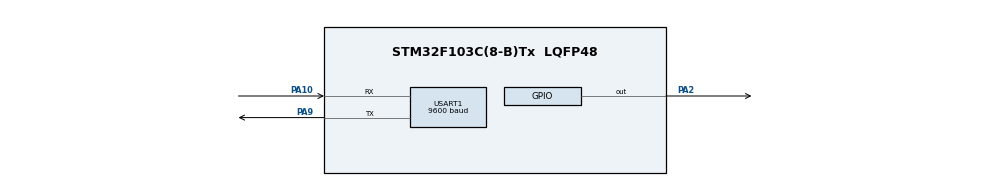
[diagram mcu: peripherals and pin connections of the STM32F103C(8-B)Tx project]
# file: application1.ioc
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Mcu.Family=STM32F1
Mcu.Name=STM32F103C(8-B)Tx
Mcu.Package=LQFP48
NVIC.PriorityGroup=NVIC_PRIORITYGROUP_4
NVIC.USART1_IRQn=true\:0\:0\:false\:false\:true\:true\:true\:true
PA10.Mode=Asynchronous
PA10.Signal=USART1_RX
PA13.Mode=Serial_Wire
PA13.Signal=SYS_JTMS-SWDIO
PA14.Mode=Serial_Wire
PA14.Signal=SYS_JTCK-SWCLK
PA2.Signal=GPIO_Output
PA9.Mode=Asynchronous
PA9.Signal=USART1_TX
ProjectManager.HeapSize=0x200
ProjectManager.StackSize=0x400
ProjectManager.TargetToolchain=STM32CubeIDE
RCC.APB1Freq_Value=8000000
RCC.APB2Freq_Value=8000000
USART1.BaudRate=9600
USART1.VirtualMode=VM_ASYNC
board=custom

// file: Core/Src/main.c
/* USER CODE BEGIN Header */
/**
  ******************************************************************************
  * @file           : main.c
  * @brief          : Main program body
  ******************************************************************************
  * @attention
  *
  * Copyright (c) 2025 STMicroelectronics.
  * All rights reserved.
  *
  * This software is licensed under terms that can be found in the LICENSE file
  * in the root directory of this software component.
  * If no LICENSE file comes with this software, it is provided AS-IS.
  *
  ******************************************************************************
  */
/* USER CODE END Header */
#include "main.h"

/* USER CODE BEGIN Includes */
#include <stdio.h>
#include <string.h>
#include <stdlib.h>
/* USER CODE END Includes */

/* USER CODE BEGIN PD */
#define FIRMWARE_VERSION			"1.0"
#define SLOT_2_ADDR					0x08009800	 //38 page
#define ADDR_OF_SLOT_NO				0x08002800   //10 page
#define Update_Firmware_Cmd			"101"
#define Stop_Update_Firmware_Cmd    "102"
/* USER CODE END PD */

UART_HandleTypeDef huart1;

/* USER CODE BEGIN PV */
char  tx_data[150] = {0};
uint32_t flash_write_data[1024];
uint32_t PageError = 0;
HAL_StatusTypeDef status = HAL_OK;

volatile char Rx_data[1]={0};
char data_buff[100]={};
volatile uint8_t startData = 0, isDataComp =0, indx=0,FirmwareUpdate=0;

int file_size = 0;
uint8_t fw_update_start=0,fw_update_cplt=0;
FLASH_EraseInitTypeDef fwupdate_EraseInitStruct = {0};
/* USER CODE END PV */

void SystemClock_Config(void);
static void MX_GPIO_Init(void);
static void MX_USART1_UART_Init(void);
/* USER CODE BEGIN PFP */
void Write_into_Flash(uint32_t addr,uint32_t data[],uint16_t size, uint32_t NbPages);

/*functions for firmware update*/
uint8_t PageErase_inFlash(int numOfPages);
/* USER CODE END PFP */

int main(void)
{

  /* MCU Configuration--------------------------------------------------------*/

  /* Reset of all peripherals, Initializes the Flash interface and the Systick. */
  HAL_Init();

  /* Configure the system clock */
  SystemClock_Config();

  /* Initialize all configured peripherals */
  MX_GPIO_Init();
  MX_USART1_UART_Init();
  /* USER CODE BEGIN 2 */
  HAL_UART_Receive_IT(&huart1,(uint8_t*)Rx_data,1);

  sprintf(tx_data,"Application 1 loaded successfully \n");
  HAL_UART_Transmit(&huart1, (uint8_t*)tx_data, strlen(tx_data), 1000);

  HAL_GPIO_WritePin(GPIOC,GPIO_PIN_13,1);

  flash_write_data[0] = 1;
  Write_into_Flash((uint32_t)ADDR_OF_SLOT_NO,flash_write_data,1,1);

  /* USER CODE END 2 */

  /* Infinite loop */
  /* USER CODE BEGIN WHILE */
  while (1)
  {
	  HAL_GPIO_TogglePin(GPIOA,GPIO_PIN_2);
	  HAL_Delay(300);
	  if(isDataComp)
	  {
	  	HAL_UART_Transmit(&huart1, (uint8_t*)data_buff,strlen(data_buff),100);
	  	sprintf(tx_data,"is there firmware update: %d\n",FirmwareUpdate);
	    HAL_UART_Transmit(&huart1, (uint8_t*)tx_data, strlen(tx_data), 1000);

	  	if(strcmp(Update_Firmware_Cmd,data_buff) == 0)
	  	{
	  		sprintf(tx_data,"*OK#");
	  		HAL_UART_Transmit(&huart1, (uint8_t*)tx_data, strlen(tx_data), 1000);
	  		FirmwareUpdate = 1;

	  	}
	  	else if(strcmp(Stop_Update_Firmware_Cmd,data_buff) == 0)
	  	{
	  		sprintf(tx_data,"\n Stopping firmware update and rebooting\n");
	  		HAL_UART_Transmit(&huart1, (uint8_t*)tx_data, strlen(tx_data), 1000);
	  	}
	  	else if(FirmwareUpdate)
	  	{
	  		file_size = atoi(data_buff);  //file size should be in bytes
	  		int x = file_size/1000;       //no. of pages
	  		sprintf(tx_data,"\n file size: %d B\n",file_size);
	  		HAL_UART_Transmit(&huart1, (uint8_t*)tx_data, strlen(tx_data), 1000);
	  		if((x > 0) && (x <= 27))
	  		{
	  			 HAL_FLASH_Unlock();
	  			 fw_update_start = PageErase_inFlash(x);
	  			 if(fw_update_start == HAL_OK)
	  			 {
	  				 sprintf(tx_data,"\n start update\n");
	  				 HAL_UART_Transmit(&huart1, (uint8_t*)tx_data, strlen(tx_data), 1000);
	  			 }
	  			 else HAL_FLASH_Lock();

	  		}
	  		FirmwareUpdate=0;
	  	}
	  	isDataComp = 0;
	  }
    /* USER CODE END WHILE */

  }
}

void SystemClock_Config(void)
{
  RCC_OscInitTypeDef RCC_OscInitStruct = {0};
  RCC_ClkInitTypeDef RCC_ClkInitStruct = {0};

  /** Initializes the RCC Oscillators according to the specified parameters
  * in the RCC_OscInitTypeDef structure.
  */
  RCC_OscInitStruct.OscillatorType = RCC_OSCILLATORTYPE_HSI;
  RCC_OscInitStruct.HSIState = RCC_HSI_ON;
  RCC_OscInitStruct.HSICalibrationValue = RCC_HSICALIBRATION_DEFAULT;
  RCC_OscInitStruct.PLL.PLLState = RCC_PLL_NONE;
  if (HAL_RCC_OscConfig(&RCC_OscInitStruct) != HAL_OK)
  {
    Error_Handler();
  }

  /** Initializes the CPU, AHB and APB buses clocks
  */
  RCC_ClkInitStruct.ClockType = RCC_CLOCKTYPE_HCLK|RCC_CLOCKTYPE_SYSCLK
                              |RCC_CLOCKTYPE_PCLK1|RCC_CLOCKTYPE_PCLK2;
  RCC_ClkInitStruct.SYSCLKSource = RCC_SYSCLKSOURCE_HSI;
  RCC_ClkInitStruct.AHBCLKDivider = RCC_SYSCLK_DIV1;
  RCC_ClkInitStruct.APB1CLKDivider = RCC_HCLK_DIV1;
  RCC_ClkInitStruct.APB2CLKDivider = RCC_HCLK_DIV1;

  if (HAL_RCC_ClockConfig(&RCC_ClkInitStruct, FLASH_LATENCY_0) != HAL_OK)
  {
    Error_Handler();
  }
}

static void MX_USART1_UART_Init(void)
{

  huart1.Instance = USART1;
  huart1.Init.BaudRate = 9600;
  huart1.Init.WordLength = UART_WORDLENGTH_8B;
  huart1.Init.StopBits = UART_STOPBITS_1;
  huart1.Init.Parity = UART_PARITY_NONE;
  huart1.Init.Mode = UART_MODE_TX_RX;
  huart1.Init.HwFlowCtl = UART_HWCONTROL_NONE;
  huart1.Init.OverSampling = UART_OVERSAMPLING_16;
  if (HAL_UART_Init(&huart1) != HAL_OK)
  {
    Error_Handler();
  }

}

static void MX_GPIO_Init(void)
{
  GPIO_InitTypeDef GPIO_InitStruct = {0};

  /* GPIO Ports Clock Enable */
  __HAL_RCC_GPIOA_CLK_ENABLE();

  /*Configure GPIO pin Output Level */
  HAL_GPIO_WritePin(GPIOA, GPIO_PIN_2, GPIO_PIN_RESET);

  /*Configure GPIO pin : PA2 */
  GPIO_InitStruct.Pin = GPIO_PIN_2;
  GPIO_InitStruct.Mode = GPIO_MODE_OUTPUT_PP;
  GPIO_InitStruct.Pull = GPIO_NOPULL;
  GPIO_InitStruct.Speed = GPIO_SPEED_FREQ_LOW;
  HAL_GPIO_Init(GPIOA, &GPIO_InitStruct);

}

/* USER CODE BEGIN 4 */
uint8_t PageErase_inFlash(int numOfPages)
{
	fwupdate_EraseInitStruct.TypeErase   	   = 	FLASH_TYPEERASE_PAGES;
	fwupdate_EraseInitStruct.PageAddress        = 	SLOT_2_ADDR ;
	fwupdate_EraseInitStruct.NbPages     	   = 	numOfPages ;

	status	=	HAL_FLASHEx_Erase(&fwupdate_EraseInitStruct, &PageError);
	if (status == HAL_OK)
	{
		HAL_UART_Transmit(&huart1, (uint8_t*)"\nFlash erased for firmware\n",
			strlen("\nFlash erased for firmware\n") , 1000);
	}
	else HAL_UART_Transmit(&huart1, (uint8_t*)"\nFlash not erased for firmware\n",
			strlen("\nFlash not erased for firmware\n") , 1000);
	return status;
}

void HAL_UART_RxCpltCallback(UART_HandleTypeDef *huart)
{
	if(huart->Instance == USART1)
	{
		if(fw_update_start)
		{
			//write the file in flash
		}
		else if(isDataComp == 0)
		{
			if(Rx_data[0] == '*')
			{
				startData = 1;
				indx=0;
			}
			else if(Rx_data[0] == '#' && startData == 1 )
			{
				if(indx>0)
					isDataComp = 1;
				data_buff[indx]='\0';
				startData = 0;
				indx=0;
			}
			else if(startData == 1)
			{
				data_buff[indx] = Rx_data[0];
				indx = indx + 1;
			}
		}

		HAL_UART_Receive_IT(&huart1,(uint8_t*)Rx_data,1);
	}

}

void HAL_UART_ErrorCallback(UART_HandleTypeDef *huart)
{
  HAL_UART_Receive_IT(&huart1,(uint8_t*)Rx_data,1);
}
void Write_into_Flash(uint32_t addr,uint32_t data[],uint16_t size, uint32_t NbPages)
{
	HAL_FLASH_Unlock();

	FLASH_EraseInitTypeDef EraseInitStruct = {0};

	EraseInitStruct.TypeErase   	   = 	FLASH_TYPEERASE_PAGES;
	EraseInitStruct.PageAddress        = 	addr ;
	EraseInitStruct.NbPages     	   = 	NbPages;

	status	=	HAL_FLASHEx_Erase(&EraseInitStruct, &PageError);
	if (status == HAL_OK)
	{
		HAL_UART_Transmit(&huart1, (uint8_t*)"valid address",
				strlen("valid address") , 100);
		for(uint16_t i=0;i<size;i++)
		{
			HAL_FLASH_Program(FLASH_TYPEPROGRAM_WORD, addr  ,data[i]);
		}
	}
	 HAL_FLASH_Lock();
	 HAL_UART_Transmit(&huart1, (uint8_t*)"return from Write_into_Flash",
			 strlen("return from Write_into_Flash") , 100);
}

void flashFirmWare()
{
}
/* USER CODE END 4 */

void Error_Handler(void)
{
  __disable_irq();
  while (1)
  {
  }
}
